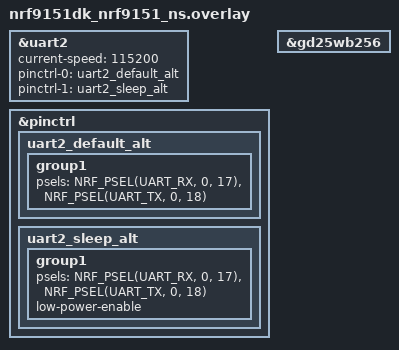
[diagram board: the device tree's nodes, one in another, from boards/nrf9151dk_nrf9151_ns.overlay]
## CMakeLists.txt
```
# SPDX-License-Identifier: Apache-2.0

cmake_minimum_required(VERSION 3.20.0)
find_package(Zephyr REQUIRED HINTS $ENV{ZEPHYR_BASE})
project(tcp_sample)

add_subdirectory(src/slip)

FILE(GLOB app_sources src/*.c)
target_sources(app PRIVATE ${app_sources})

include(${ZEPHYR_BASE}/samples/net/common/common.cmake)
```

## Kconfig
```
#
# Copyright (c) 2020 Nordic Semiconductor ASA
#
# SPDX-License-Identifier: LicenseRef-Nordic-5-Clause
#

menu "TCP Sample Settings"

config TCP_DATA_UPLOAD_MAX_SIZE_BYTES
	int "Max number of bytes transmitted to the server"
	default 512

config TCP_DATA_UPLOAD_FREQUENCY_SECONDS
	int "How often data is transmitted to the server"
	default 900

config TCP_DATA_UPLOAD_ITERATIONS
	int "Number of data transmissions to the server before shutdown"
	range -1 2147483647
	default -1
	help
	  Number of data transmissions to the server before shutdown.
	  Set to -1 to transmit indefinitely.

config TCP_SERVER_ADDRESS_STATIC
	string "TCP server IP address"
	default "8.8.8.8"

config TCP_SERVER_PORT
	int "TCP server port number"
	default "2469"

config TCP_POLL_TIME
	int "Poll time-out in seconds for TCP connection"
	default "60"

config TCP_PSM_ENABLE
	bool "Enable LTE Power Saving Mode (PSM)"
	default y
	select LTE_PSM_REQ

config TCP_EDRX_ENABLE
	bool "Enable LTE enhanced Discontinuous Reception (eDRX)"
	select LTE_EDRX_REQ

config TCP_RAI_ENABLE
	bool "Enable LTE Release Assistance Indication (RAI)"
	default y
	select LTE_RAI_REQ

if TCP_RAI_ENABLE

choice TCP_RAI_INDICATION
	prompt "RAI indication to set for TCP transmission"
	default TCP_RAI_LAST

config TCP_RAI_NO_DATA
	bool "Indicates that there will be no upcoming data transmission anymore"

config TCP_RAI_LAST
	bool "Indicates that the next transmission will be the last one for some time"

config TCP_RAI_ONGOING
	bool "Indicates that the client expects to use the socket more after the next transmission"

endchoice

endif # UDP_RAI_ENABLE

endmenu

module = TCP
module-str = TCP sample
source "${ZEPHYR_BASE}/subsys/logging/Kconfig.template.log_config"

menu "Zephyr Kernel"
source "Kconfig.zephyr"
endmenu
```

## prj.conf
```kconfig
# General config
CONFIG_REQUIRES_FULL_LIBC=y
# Heap and stacks
CONFIG_HEAP_MEM_POOL_SIZE=10240
CONFIG_MAIN_STACK_SIZE=8192
CONFIG_SYSTEM_WORKQUEUE_STACK_SIZE=4096

# Default app to debug logging
CONFIG_LOG=y
CONFIG_TCP_LOG_LEVEL_DBG=y

# Networking config
CONFIG_NETWORKING=y
CONFIG_NET_IPV4=y
CONFIG_NET_IPV6=y
CONFIG_NET_TCP=y
CONFIG_NET_SOCKETS=y
# CONFIG_NET_SOCKETS_POLL_MAX=5

CONFIG_POSIX_API=y

# Network driver config
CONFIG_TEST_RANDOM_GENERATOR=y


# UART interface
CONFIG_SERIAL=y
CONFIG_UART_USE_RUNTIME_CONFIGURE=y
CONFIG_UART_ASYNC_API=y
CONFIG_NRFX_TIMER2=y
CONFIG_RING_BUFFER=y


# Flash
CONFIG_FLASH=y
CONFIG_FLASH_PAGE_LAYOUT=y
CONFIG_MPU_ALLOW_FLASH_WRITE=y
CONFIG_FLASH_MAP=y
CONFIG_FCB=y
CONFIG_SOC_FLASH_NRF_EMULATE_ONE_BYTE_WRITE_ACCESS=y

# mcuboot
CONFIG_BOOTLOADER_MCUBOOT=y
CONFIG_STREAM_FLASH=y
CONFIG_IMG_MANAGER=y
CONFIG_MCUBOOT_IMG_MANAGER=y

#application
CONFIG_TCP_DATA_UPLOAD_FREQUENCY_SECONDS=30
CONFIG_TCP_DATA_UPLOAD_ITERATIONS=100
CONFIG_TCP_POLL_TIME=5

# my test server
# CONFIG_TCP_SERVER_ADDRESS_STATIC="182.61.144.86"
# CONFIG_TCP_SERVER_PORT=50005

# custom server
CONFIG_TCP_SERVER_ADDRESS_STATIC="34.94.214.133"
CONFIG_TCP_SERVER_PORT=8089
```

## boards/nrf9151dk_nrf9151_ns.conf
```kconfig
#
# Copyright (c) 2020 Nordic Semiconductor ASA
#
# SPDX-License-Identifier: LicenseRef-Nordic-5-Clause
#

# General config
CONFIG_PICOLIBC_IO_FLOAT=y
CONFIG_NCS_SAMPLES_DEFAULTS=y
CONFIG_SERIAL=y

# Network
CONFIG_NETWORKING=y
CONFIG_NET_NATIVE=n
CONFIG_NET_SOCKETS=y
CONFIG_NET_SOCKETS_OFFLOAD=y

# LTE link control
CONFIG_LTE_LINK_CONTROL=y
CONFIG_LTE_NETWORK_MODE_NBIOT_GPS=y
CONFIG_PDN=y 
CONFIG_PDN_LEGACY_PCO=y 

# Modem library
CONFIG_NRF_MODEM_LIB=y

# LTE parameters
## PSM
CONFIG_TCP_PSM_ENABLE=n
#Requested periodic TAU of 10 minutes for PSM
CONFIG_LTE_PSM_REQ_RPTAU="00000001"
#Requested active time of 3 minutes for PSM
CONFIG_LTE_PSM_REQ_RAT="00100011"

## eDRX@81.92S
CONFIG_TCP_EDRX_ENABLE=n
CONFIG_LTE_EDRX_REQ_VALUE_NBIOT="0101"   
# Request Paging time window of 2.56 seconds for NB-IoT
CONFIG_LTE_PTW_VALUE_NBIOT="0000"    

## RAI
CONFIG_TCP_RAI_ENABLE=n

CONFIG_NRF_MODEM_LIB_LOG_FW_VERSION_UUID=y
```

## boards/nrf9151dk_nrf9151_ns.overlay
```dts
/*
 * Copyright (c) 2024 Nordic Semiconductor ASA
 *
 * SPDX-License-Identifier: LicenseRef-Nordic-5-Clause
 */
//  / {
// 	chosen {
// 		ncs,slm-uart = &uart2;
// 	};
// };

&uart2 {
	current-speed = <115200>;
	status = "okay";
	pinctrl-0 = <&uart2_default_alt>; /* <&interface_to_nrf52840 1 0> */
	pinctrl-1 = <&uart2_sleep_alt>; /* <&interface_to_nrf52840 0 0> */
	pinctrl-names = "default", "sleep";
};

&pinctrl {
	uart2_default_alt: uart2_default_alt {
		group1 {
			psels = <NRF_PSEL(UART_RX, 0, 17)>,
				<NRF_PSEL(UART_TX, 0, 18)>;
		};
	};

	uart2_sleep_alt: uart2_sleep_alt {
		group1 {
			psels = <NRF_PSEL(UART_RX, 0, 17)>,
				<NRF_PSEL(UART_TX, 0, 18)>;
			low-power-enable;
		};
	};
};






//  / {
// 	sensor_sim: sensor-sim {
// 		compatible = "nordic,sensor-sim";
// 		status = "okay";
// 		acc-signal = "wave";
// 	};

// 	measure {
// 		compatible = "nordic,nrf-pinctrl";
// 		en {
// 			compatible = "gpio-leds";
// 			measure_en: measure_en {
// 				gpios = <&gpio0 16 0x0>;
// 				label = "measure_en";
// 			};
// 		};
// 		signal {
// 			compatible = "gpio-keys";
// 			signal1: signal_1 {
// 				// gpios = <&gpio0 13 0x1>;			//for 9160DK
// 				gpios = <&gpio0 6 0x1>;				//for 9151dk
// 				label = "signal_1";
// 			};
// 			signal2: signal_2 {
// 				// gpios = <&gpio0 15 0x1>;			//for 9160DK
// 				gpios = <&gpio0 7 0x1>;				//for 9151dk
// 				label = "signal_2";
// 			};
// 		};
// 	};
// };


// &gpio0 {
// 	status = "okay";
// 	sense-edge-mask = < 0x4040 >;
//  };



// &led0 {
// 	gpios = <&gpio0 2 0>;
// };



// &uart2 {
// 	current-speed = <1000000>;
// 	status = "okay";
// 	pinctrl-0 = <&uart2_default_alt>; /* <&interface_to_nrf52840 1 0> */
// 	pinctrl-1 = <&uart2_sleep_alt>; /* <&interface_to_nrf52840 0 0> */
// 	pinctrl-names = "default", "sleep";

// 	lpuart: nrf-sw-lpuart {
// 		compatible = "nordic,nrf-sw-lpuart";
// 		status = "okay";
// 		req-pin = <21>; /* <&interface_to_nrf52840 3 0>; */
// 		rdy-pin = <19>; /* <&interface_to_nrf52840 2 0>; */
// 	};
// };

// &pinctrl {
// 	uart2_default_alt: uart2_default_alt {
// 		group1 {
// 			psels = <NRF_PSEL(UART_RX, 0, 17)>,
// 				<NRF_PSEL(UART_TX, 0, 18)>;
// 		};
// 	};

// 	uart2_sleep_alt: uart2_sleep_alt {
// 		group1 {
// 			psels = <NRF_PSEL(UART_RX, 0, 17)>,
// 				<NRF_PSEL(UART_TX, 0, 18)>;
// 			low-power-enable;
// 		};
// 	};
// };








/* External flash device is disabled by default */
&gd25wb256 {
	status = "okay";
};
```

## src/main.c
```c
/*
 * Copyright (c) 2020 Nordic Semiconductor ASA
 *
 * SPDX-License-Identifier: LicenseRef-Nordic-5-Clause
 */

#include <stdio.h>
#include <zephyr/kernel.h>
#include <zephyr/net/socket.h>
#include <zephyr/drivers/uart.h>
#include <modem/lte_lc.h>
#include <modem/nrf_modem_lib.h>
#include <nrf_modem_at.h>

#include "app.h"


#define FW_VERSION			"1.0.0"


K_SEM_DEFINE(lte_connected_sem, 0, 1);
K_SEM_DEFINE(modem_shutdown_sem, 0, 1);


/** Below code can be work as a timer */
#if 0

static struct k_work_delayable socket_transmission_work;
static int data_upload_iterations = CONFIG_TCP_DATA_UPLOAD_ITERATIONS;

static void socket_transmission_work_fn(struct k_work *work)
{
	printk("socket_transmission_work_fn[%d] been triggeded at %lld,\r\n ",data_upload_iterations,k_ticks_to_ms_floor64(k_uptime_ticks()));

	/* Transmit a limited number of times and then shutdown. */
	if (data_upload_iterations > 0) {
		data_upload_iterations--;
	} else if (data_upload_iterations == 0) {
		k_sem_give(&modem_shutdown_sem);
		/* No need to schedule work if we're shutting down. */
		return;
	}

	/* Schedule work if we're either transmitting indefinitely or
	 * there are more iterations left.
	 */
	k_work_schedule(&socket_transmission_work,
			K_SECONDS(CONFIG_TCP_DATA_UPLOAD_FREQUENCY_SECONDS));
}


static void work_init(void)
{
	k_work_init_delayable(&socket_transmission_work, socket_transmission_work_fn);
}

#endif

static void lte_handler(const struct lte_lc_evt *const evt)
{
	switch (evt->type) {
	case LTE_LC_EVT_NW_REG_STATUS:
		if ((evt->nw_reg_status != LTE_LC_NW_REG_REGISTERED_HOME) &&
		    (evt->nw_reg_status != LTE_LC_NW_REG_REGISTERED_ROAMING)) {
			break;
		}

		printk("Network registration status: %s\n",
		       evt->nw_reg_status == LTE_LC_NW_REG_REGISTERED_HOME ?
		       "Connected - home" : "Connected - roaming");
		k_sem_give(&lte_connected_sem);

		// k_work_schedule(&socket_transmission_work, K_SECONDS(5));
		break;
	case LTE_LC_EVT_PSM_UPDATE:
		printk("PSM parameter update: TAU: %d s, Active time: %d s\n",
		       evt->psm_cfg.tau, evt->psm_cfg.active_time);
		break;
	case LTE_LC_EVT_EDRX_UPDATE:
		printk("eDRX parameter update: eDRX: %.2f s, PTW: %.2f s\n",
		       (double)evt->edrx_cfg.edrx, (double)evt->edrx_cfg.ptw);
		break;
	case LTE_LC_EVT_RRC_UPDATE:
		printk("RRC mode: %s\n",
		       evt->rrc_mode == LTE_LC_RRC_MODE_CONNECTED ? "Connected" : "Idle\n");
		break;
	case LTE_LC_EVT_CELL_UPDATE:
		printk("LTE cell changed: Cell ID: %d, Tracking area: %d\n",
		       evt->cell.id, evt->cell.tac);
		break;
	default:
		break;
	}
}


static void modem_connect(void)
{
	int ret = 0;

	do {
		printk("\nConnecting to network.This may take several minutes.\n");

		ret = lte_lc_connect();
		if (ret < 0) {
			printk("Failed to establish LTE connection (%d).", ret);
			printk("Will retry in a minute.");
			lte_lc_offline();
			k_sleep(K_SECONDS(60));
		} else {
			enum lte_lc_lte_mode mode;

			lte_lc_lte_mode_get(&mode);
			if (mode == LTE_LC_LTE_MODE_NBIOT) {
				printk("Connected to NB-IoT network.\n");
			} else if (mode == LTE_LC_LTE_MODE_LTEM) {
				printk("Connected to LTE network.\n");
			} else  {
				printk("Connected to unknown network.\n");
			}
			k_sem_give(&lte_connected_sem);
		}
	} while (ret < 0);
}


int main(void)
{
	int err;

	printk("\nTCP sample has started, version is %s.\n\n",FW_VERSION);

	// work_init();

	err = nrf_modem_lib_init();
	if (err) {
		printk("Failed to initialize modem library, error: %d\n", err);
		return -1;
	}

	err = lte_lc_connect_async(lte_handler);
	if (err) {
		printk("Failed to connect to LTE network, error: %d\n", err);
		return -1;
	}

	uart_handler_init();
	
	while (true) 
	{
		/* Set network state to start for blocking LTE */
		if (reconnect) {
			reconnect = false;

			printk("LTE connection error. The sample will try to re-establish network connection.\n");

			/* Try to reconnect to the network. */
			err = lte_lc_offline();
			if (err < 0) {
				printk("Failed to put LTE link in offline state (%d)\n", err);
			}
			modem_connect();
		}

		/** This part code may not excute, just for low power use api */
		if( 0 == k_sem_take(&modem_shutdown_sem, K_SECONDS(2)))
		{
			/** we should suspend the tcp thread */
			// k_thread_suspend(tcp_thread);

			err = nrf_modem_lib_shutdown();
			if (err) {
				return -1;
			}	
		}
	}	

	return 0;
}
```

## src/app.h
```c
/*
 * Copyright (c) 2020 Nordic Semiconductor ASA
 *
 * SPDX-License-Identifier: LicenseRef-Nordic-5-Clause
 */

#ifndef __APP_H_
#define __APP_H_


typedef struct {
	uint8_t *data;
	uint16_t length;
} socket_data_t;


extern const k_tid_t tcp_thread; 

extern struct k_sem lte_connected_sem;

extern struct k_sem modem_shutdown_sem;

extern struct k_msgq tx_send_queue;

extern struct k_msgq rx_event_queue;

extern bool reconnect;


extern int uart_tx_write(const uint8_t *data, size_t len);


extern int uart_handler_init(void);



#endif /* _APP_H */
```

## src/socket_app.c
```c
/*
 * Copyright (c) 2017 Linaro Limited
 *
 * SPDX-License-Identifier: Apache-2.0
 */

#include <stdio.h>
#include <stdbool.h>
#include <errno.h>
#include <stdlib.h>
#include <zephyr/posix/fcntl.h>
#include <zephyr/net/socket.h>
#include <zephyr/kernel.h>
#include <zephyr/logging/log.h>
LOG_MODULE_REGISTER(tcp_sample, CONFIG_TCP_LOG_LEVEL);

#include "app.h"

// #ifdef CONFIG_NET_IPV6
// #define USE_IPV6
// #endif

#define TCP_THREAD_STACK_SIZE               4096
#define TCP_THREAD_PRIORITY 				5

#define TX_QUEUE_COUNT						20


K_MSGQ_DEFINE(tx_send_queue, sizeof(socket_data_t), TX_QUEUE_COUNT, 4);

bool reconnect = false;


static int do_tcp_send(int sock, const uint8_t *data, int datalen)
{
	int ret = 0;
	uint32_t offset = 0;

	while (offset < datalen) {
		ret = send(sock, data + offset, datalen - offset, 0);
		if (ret < 0) {
			LOG_ERR("send() failed: %d, sent: %d", -errno, offset);
			ret = -errno;
			break;
		} else {
			// LOG_INF("Socket send data length = %d\n", ret);
			offset += ret;
		}
	}

	return ret;
}


static void receive_data_handle(uint8_t *data, uint16_t length)
{
	LOG_INF("Received %d bytes data from tcp server, data_segment:\"%s\"\n", length, data);
}


/* tcp client task */
static void tcp_thread_fn(void)
{
	int ret = 0;
	struct pollfd fds[2];
	int client_socket = 0;
	uint8_t rec_buf[512] = {0};  /* For socket receive data. */
	
	k_sem_take(&lte_connected_sem, K_FOREVER);

retry:
	LOG_WRN("LTE connected successfully, now we start tcp task!!!\n");

#if !defined(USE_IPV6)
	struct sockaddr_in server_addr = {0};

	client_socket = socket(AF_INET, SOCK_STREAM, IPPROTO_TCP);
	if (client_socket < 0) {
		printf("error: socket(AF_INET): %d\n", errno);
		goto error_exit;
	}
	struct timeval socket_timeout = {.tv_sec = 3};

	ret = setsockopt(client_socket, SOL_SOCKET, SO_SNDTIMEO, &socket_timeout, sizeof(socket_timeout));
	if (ret) {
		LOG_ERR("setsockopt(%d) error: %d", SO_SNDTIMEO, -errno);
		ret = -errno;
		goto error_exit;
	}

	
	server_addr.sin_family = AF_INET;
	server_addr.sin_port = htons(CONFIG_TCP_SERVER_PORT);
	inet_pton(AF_INET, CONFIG_TCP_SERVER_ADDRESS_STATIC,&server_addr.sin_addr);

	ret = connect(client_socket, (struct sockaddr *)&server_addr, sizeof(struct sockaddr_in));
	if (ret) {
		LOG_ERR("AF_INET connect() failed: %d", -errno);
		goto error_exit;
	}
#else
	struct sockaddr_in6 server_addr = {0};

	client_socket = socket(AF_INET6, SOCK_STREAM, IPPROTO_TCP);
	if (client_socket < 0) {
		printf("error: socket(AF_INET6): %d\n", errno);
		goto error_exit;
	}
	server_addr.sin6_family = AF_INET6;
	server_addr.sin6_port = htons(CONFIG_TCP_SERVER_PORT);
	inet_pton(AF_INET6, CONFIG_TCP_SERVER_ADDRESS_STATIC,&server_addr.sin6_addr);

	ret = connect(client_socket, (struct sockaddr *)&server_addr, sizeof(struct sockaddr_in6));
	if (ret) {
		LOG_ERR("AF_INET6 connect() failed: %d", -errno);
		goto error_exit;
	}
#endif
	
	fds[0].fd = client_socket;
	fds[0].events = POLLIN;

	while (1) {
		// ret = poll(fds, ARRAY_SIZE(fds), MSEC_PER_SEC * CONFIG_TCP_POLL_TIME);
		ret = poll(fds, ARRAY_SIZE(fds), 200);
		if (ret < 0) {
			LOG_WRN("poll() error: %d", ret);
			break;
		}
		else if (ret == 0) {
			/* timeout */
			// LOG_INF("TCP wait for poll event timeout at %lld.\n",k_ticks_to_ms_floor64(k_uptime_ticks()));
		}
		else{
			// LOG_DBG("[%d]sock events 0x%08x at %lld.\n", ret,fds[0].revents,k_ticks_to_ms_floor64(k_uptime_ticks()));
			if ((fds[0].revents & POLLIN) != 0) {
				/* receive data from server */
				memset(rec_buf, 0, sizeof(rec_buf));
				ret = recv(fds[0].fd, (void *)rec_buf, sizeof(rec_buf), MSG_DONTWAIT);
				if (ret < 0 && errno != EAGAIN) {
					LOG_WRN("recv() error: %d", -errno);
				} else if (ret > 0) {
					/** handle the received data from tcp server */
					receive_data_handle(rec_buf, ret);
				}
			}
			if ((fds[0].revents & POLLERR) != 0) {
				LOG_WRN("SOCK (%d): POLLERR", fds[0].fd);
				break;
			}
			if ((fds[0].revents & POLLNVAL) != 0) {
				LOG_WRN("SOCK (%d): POLLNVAL", fds[0].fd);
				break;
			}
			if ((fds[0].revents & POLLHUP) != 0) {
				/* Lose LTE connection / remote end close */
				LOG_WRN("SOCK (%d): POLLHUP", fds[0].fd);
				reconnect = true;
				k_sem_take(&lte_connected_sem, K_FOREVER);
				break;
			}
		}

		/***************** Events to send message queue. *****************************/
		{
			static uint8_t resend_count = 0;
			socket_data_t send_packet = {0};
			if (k_msgq_peek(&tx_send_queue, &send_packet) == 0)  
			{
				// LOG_INF("[%d]:%s\n",send_packet.length, send_packet.data);
				ret = do_tcp_send(client_socket, send_packet.data, send_packet.length);
				if(ret == send_packet.length)
				{
					/* send successfully, delete the queue message and free memory */
					k_msgq_get(&tx_send_queue, &send_packet, K_NO_WAIT);
					k_free(send_packet.data);
					resend_count = 0;
					LOG_DBG("Socket send [%d] successfully , the data is: \"%s\"\n",ret, send_packet.data);
				}
				else if(ret <= 0)
				{
					if(resend_count++ >= 3)
					{
						LOG_WRN("Socket has something wrong, we'd better reconnect it.\n");
						break;
					}
				}
			}
		}
	}

error_exit:
	if(client_socket)
	{
		close(client_socket);
	}
	k_sleep(K_SECONDS(3));	
	goto retry;
}




K_THREAD_DEFINE(tcp_thread, TCP_THREAD_STACK_SIZE,
		tcp_thread_fn, NULL, NULL, NULL,
		TCP_THREAD_PRIORITY, 0, 0);
```

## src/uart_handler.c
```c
/*
 * Copyright (c) 2023 Nordic Semiconductor ASA
 *
 * SPDX-License-Identifier: LicenseRef-Nordic-5-Clause
 */

#include <zephyr/kernel.h>
#include <stdio.h>
#include <zephyr/drivers/uart.h>
#include <hal/nrf_uarte.h>
#include <hal/nrf_gpio.h>
#include <zephyr/sys/ring_buffer.h>
#include <zephyr/pm/device.h>

#include <zephyr/logging/log.h>
LOG_MODULE_REGISTER(uart_handler, CONFIG_TCP_LOG_LEVEL);
#include "slip/slip.h"
#include "app.h"


#define UART_RX_TIMEOUT_US					50000
#define UART_ERROR_DELAY_MS					500
#define UART_RX_EVENT_COUNT_FOR_BUF 		20

#define UART_SLIP_MTU						512

#define UART_SLAB_BLOCK_SIZE 				sizeof(struct rx_buf_t)
#define UART_SLAB_BLOCK_COUNT 				3


const struct device *const uart_dev = DEVICE_DT_GET(DT_NODELABEL(uart2));
uint32_t uart_baudrate;

static struct k_work_delayable rx_process_work;

struct rx_buf_t {
	atomic_t ref_counter;
	size_t len;
	uint8_t buf[512];
};

struct rx_event_t {
	uint8_t *buf;
	size_t len;
};

enum uart_recovery_state {
	RECOVERY_IDLE,
	RECOVERY_ONGOING,
	RECOVERY_DISABLED
};

static atomic_t recovery_state;

static uint8_t slip_buffer[UART_SLIP_MTU];
static slip_t m_slip = {
	.state = SLIP_STATE_DECODING, 
	.p_buffer = slip_buffer,
	.current_index = 0,
	.buffer_len = sizeof(slip_buffer)};

K_MEM_SLAB_DEFINE(rx_slab, UART_SLAB_BLOCK_SIZE, UART_SLAB_BLOCK_COUNT, 4);

K_SEM_DEFINE(tx_done_sem, 0, 1);

K_MSGQ_DEFINE(rx_event_queue, sizeof(struct rx_event_t), 8, 4);

RING_BUF_DECLARE(tx_buf, 256);

/* Protects the tx_buf from multiple writes. */
K_MUTEX_DEFINE(mutex_tx_put); 

static inline struct rx_buf_t *block_start_get(uint8_t *buf)
{
	size_t block_num;

	/* blocks are fixed size units from a continuous memory slab: */
	/* round down to the closest unit size to find beginning of block. */

	block_num = (((size_t)buf - (size_t)rx_slab.buffer) / UART_SLAB_BLOCK_SIZE);

	return (struct rx_buf_t *) &rx_slab.buffer[block_num * UART_SLAB_BLOCK_SIZE];
}

static struct rx_buf_t *rx_buf_alloc(void)
{
	struct rx_buf_t *buf;
	int err;

	/* Async UART driver returns pointers to received data as */
	/* offsets from beginning of RX buffer block. */
	/* This code uses a reference counter to keep track of the number of */
	/* references within a single RX buffer block */

	err = k_mem_slab_alloc(&rx_slab, (void **) &buf, K_NO_WAIT);
	if (err) {
		return NULL;
	}

	atomic_set(&buf->ref_counter, 1);

	return buf;
}

static void rx_buf_ref(void *buf)
{
	atomic_inc(&(block_start_get(buf)->ref_counter));
}

static void rx_buf_unref(void *buf)
{
	struct rx_buf_t *uart_buf = block_start_get(buf);
	atomic_t ref_counter = atomic_dec(&uart_buf->ref_counter);

	/* ref_counter is the uart_buf->ref_counter value prior to decrement */
	if (ref_counter == 1) {
		k_mem_slab_free(&rx_slab, (void *)uart_buf);
	}
}

static int rx_enable(void)
{
	struct rx_buf_t *buf;
	int ret;

	buf = rx_buf_alloc();
	if (!buf) {
		LOG_ERR("UART RX failed to allocate buffer");
		return -ENOMEM;
	}

	ret = uart_rx_enable(uart_dev, buf->buf, sizeof(buf->buf), UART_RX_TIMEOUT_US);
	if (ret) {
		LOG_ERR("UART RX enable failed: %d", ret);
		return ret;
	}

	return 0;
}

static int rx_disable(void)
{
	int err;

	/* Wait for possible rx_enable to complete. */
	if (atomic_set(&recovery_state, RECOVERY_DISABLED) == RECOVERY_ONGOING) {
		k_sleep(K_MSEC(10));
	}

	err = uart_rx_disable(uart_dev);
	if (err) {
		LOG_ERR("UART RX disable failed: %d", err);
		atomic_set(&recovery_state, RECOVERY_IDLE);
		return err;
	}

	return 0;
}

static void rx_recovery(void)
{
	int err;

	if (atomic_get(&recovery_state) != RECOVERY_ONGOING) {
		return;
	}

	err = rx_enable();
	if (err) {
		k_work_schedule(&rx_process_work, K_MSEC(20));
		return;
	}

	atomic_cas(&recovery_state, RECOVERY_ONGOING, RECOVERY_IDLE);
}


static void on_packet_received(uint8_t *buffer, uint16_t length)
{
	int err;
	socket_data_t send_buffer = {0};
	
	send_buffer.data = k_calloc(length+1, sizeof(uint8_t));
	if (send_buffer.data != NULL) 
	{
		memcpy(send_buffer.data, buffer, length);		
		send_buffer.length = length;

		if(0 == k_msgq_num_free_get(&tx_send_queue))
		{
			/* message queue is full ,we have to delete the oldest data to reserve room for the new data */
			socket_data_t data_buffer = {0};
			k_msgq_get(&tx_send_queue, &data_buffer, K_NO_WAIT);
			LOG_DBG("Droped data:[%d]:%s\n",data_buffer.length, data_buffer.data);
			k_free(data_buffer.data);
		}

		/** send the uart data to tcp server*/
		err = k_msgq_put(&tx_send_queue, &send_buffer, K_NO_WAIT);
		if (err) {
			LOG_ERR("Message sent error: %d", err);
			k_free(send_buffer.data);
		}
	} 
	else 
	{
		LOG_ERR("Memory not allocated!\n");
	}
}


/** Before uart send data, the data should be enpacket by SLIP protocol */
static void uart_send_data(uint8_t *buffer, uint16_t length)
{
	static uint8_t send_buffer[UART_SLIP_MTU] = {0};
	uint32_t send_length = 0;

	slip_encode(send_buffer, buffer, length, &send_length);
	uart_tx_write(send_buffer, send_length);
}


static void rx_process(struct k_work *work)
{
	uint16_t i = 0;
	struct rx_event_t rx_event;
	int ret_code = 0;

	while (k_msgq_get(&rx_event_queue, &rx_event, K_NO_WAIT) == 0) 
	{
		// LOG_INF("Uart received:[%d]:%s\n",rx_event.len, rx_event.buf);
		for(i=0; i<rx_event.len; i++)
		{
			ret_code = slip_decode_add_byte(&m_slip, rx_event.buf[i]);
			switch (ret_code)
			{
			case NRF_SUCCESS:
				/** decode uart data success, now put it to message queue */
				on_packet_received(m_slip.p_buffer, m_slip.current_index);
				uart_send_data(m_slip.p_buffer, m_slip.current_index);		//uart send back the received data with lwip protocal, just for test
				
				memset(m_slip.p_buffer, 0, m_slip.buffer_len);
				m_slip.current_index = 0;
        		m_slip.state = SLIP_STATE_DECODING;
				break;
			// fall through
			case ERROR_NO_MEM:
				m_slip.current_index = 0;
				m_slip.state = SLIP_STATE_DECODING;
				break;
			default:
				break;
			}
		}

		rx_buf_unref(rx_event.buf);
	}

	rx_recovery();
}

static int tx_start(void)
{
	uint8_t *buf;
	size_t len;
	int err;
	enum pm_device_state state = PM_DEVICE_STATE_OFF;

	pm_device_state_get(uart_dev, &state);
	if (state != PM_DEVICE_STATE_ACTIVE) {
		return 1;
	}

	len = ring_buf_get_claim(&tx_buf, &buf, ring_buf_capacity_get(&tx_buf));
	err = uart_tx(uart_dev, buf, len, SYS_FOREVER_US);
	if (err) {
		LOG_ERR("UART TX error: %d", err);
		ring_buf_get_finish(&tx_buf, 0);
		return err;
	}
	// else
	// {
	// 	LOG_ERR("UART TX [%d] bytes Succeed!", len);
	// }

	return 0;
}

static void uart_callback(const struct device *dev, struct uart_event *evt, void *user_data)
{
	struct rx_buf_t *buf;
	struct rx_event_t rx_event;
	int err;

	ARG_UNUSED(dev);
	ARG_UNUSED(user_data);

	switch (evt->type) {
	case UART_TX_DONE:
	case UART_TX_ABORTED:
		err = ring_buf_get_finish(&tx_buf, evt->data.tx.len);
		if (err) {
			LOG_ERR("UART_TX_%s failure: %d",
				(evt->type == UART_TX_DONE) ? "DONE" : "ABORTED", err);
		}
		if (ring_buf_is_empty(&tx_buf) == false) {
			tx_start();
		} 
		
		k_sem_give(&tx_done_sem);
		break;
	case UART_RX_RDY:
		rx_buf_ref(evt->data.rx.buf);		
		rx_event.buf = &evt->data.rx.buf[evt->data.rx.offset];
		rx_event.len = evt->data.rx.len;
		err = k_msgq_put(&rx_event_queue, &rx_event, K_NO_WAIT);
		if (err) {
			LOG_ERR("UART_RX_RDY failure: %d, dropped: %d", err, evt->data.rx.len);
			rx_buf_unref(evt->data.rx.buf);
			break;
		}
		(void)k_work_submit((struct k_work *)&rx_process_work);
		break;
	case UART_RX_BUF_REQUEST:
		buf = rx_buf_alloc();
		if (!buf) {
			LOG_WRN("Disabling UART RX: No free buffers.");
			break;
		}
		err = uart_rx_buf_rsp(uart_dev, buf->buf, sizeof(buf->buf));
		if (err) {
			LOG_WRN("Disabling UART RX: %d", err);
			rx_buf_unref(buf);
		}
		break;
	case UART_RX_BUF_RELEASED:
		if (evt->data.rx_buf.buf) {
			rx_buf_unref(evt->data.rx_buf.buf);
		}
		break;
	case UART_RX_DISABLED:
		if (atomic_cas(&recovery_state, RECOVERY_IDLE, RECOVERY_ONGOING)) {
			k_work_submit((struct k_work *)&rx_process_work);
		}
		break;
	default:
		break;
	}
}

/* Write the data to tx_buffer and trigger sending. */
int uart_tx_write(const uint8_t *data, size_t len)
{
	size_t ret;
	size_t sent = 0;
	int err;

	k_mutex_lock(&mutex_tx_put, K_FOREVER);
	while (sent < len) {
		ret = ring_buf_put(&tx_buf, data + sent, len - sent);
		if (ret) {
			sent += ret;
		} else {
			/* Buffer full, block and start TX. */
			k_sem_take(&tx_done_sem, K_FOREVER);
			err = tx_start();
			if (err) {
				LOG_ERR("TX buf overflow, %d dropped. Unable to send: %d",
					len - sent,
					err);
				k_sem_give(&tx_done_sem);
				k_mutex_unlock(&mutex_tx_put);
				return err;
			}
		}
	}
	k_mutex_unlock(&mutex_tx_put);

	if (k_sem_take(&tx_done_sem, K_NO_WAIT) == 0) {
		err = tx_start();
		if (err == 1) {
			k_sem_give(&tx_done_sem);
			return 0;
		} else if (err) {
			LOG_ERR("TX start failed: %d", err);
			k_sem_give(&tx_done_sem);
			return err;
		}
	} else {
		/* TX already in progress. */
	}

	return 0;
}

int uart_handler_init(void)
{
	int err;
	uint32_t start_time;
	struct uart_config cfg;

	if (!device_is_ready(uart_dev)) {
		LOG_ERR("UART device not ready");
		return -ENODEV;
	}

	err = uart_config_get(uart_dev, &cfg);
	if (err) {
		LOG_ERR("uart_config_get: %d", err);
		return err;
	}

	uart_baudrate = cfg.baudrate;
	LOG_INF("UART baud: %d d/p/s-bits: %d/%d/%d HWFC: %d",
		cfg.baudrate, cfg.data_bits, cfg.parity,
		cfg.stop_bits, cfg.flow_ctrl);

	/* Wait for the UART line to become valid */
	start_time = k_uptime_get_32();
	do {
		err = uart_err_check(uart_dev);
		if (err) {
			uint32_t now = k_uptime_get_32();

			if (now - start_time > UART_ERROR_DELAY_MS) {
				LOG_ERR("UART check failed: %d", err);
				return -EIO;
			}
			k_sleep(K_MSEC(10));
		}
	} while (err);
	err = uart_callback_set(uart_dev, uart_callback, NULL);
	if (err) {
		LOG_ERR("Cannot set callback: %d", err);
		return -EFAULT;
	}
	(void)atomic_set(&recovery_state, RECOVERY_IDLE);
	err = rx_enable();
	if (err) {
		return -EFAULT;
	}

	k_work_init_delayable(&rx_process_work, rx_process);

	k_sem_give(&tx_done_sem);

	return 0;
}
```
